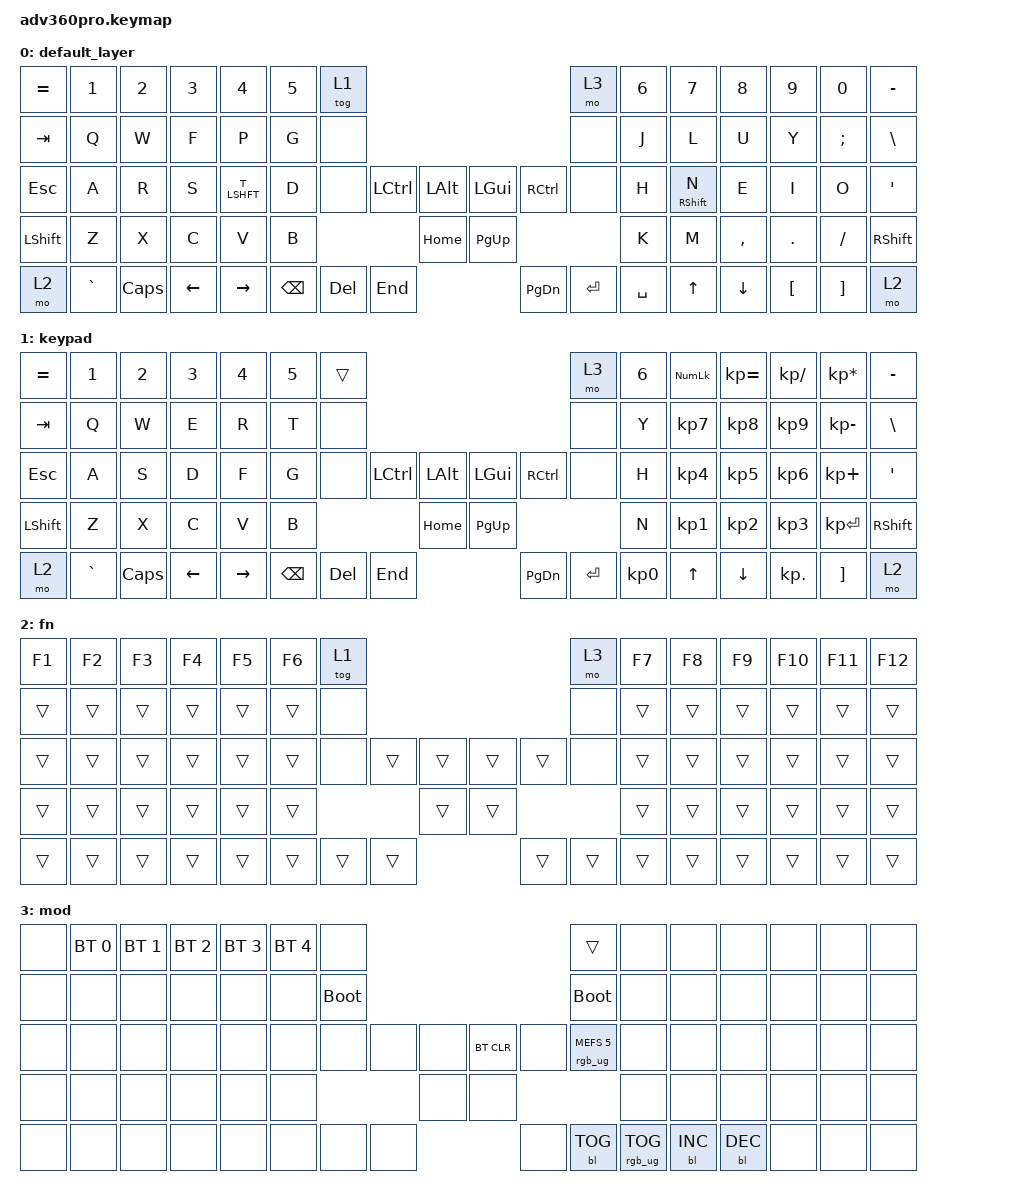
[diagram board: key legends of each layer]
#include "adv360pro_keypos.h"
#include "zmk_helper.h"

#define ___ &trans

/* Layer references  */
#define COLEMAK 0
#define QWERTY 1
#define NUM 2
#define SYM 3
#define FN 4
#define MOD 5
#define MS 6
#define NAV 7

/* Global settings */
#include "general.h"

/* Home row mods */
#include "homerow_mods.h"

/* Macros and shortcuts */
#include "custom_behaviors.h"
#include <behaviors.dtsi>
#include <dt-bindings/zmk/backlight.h>
#include <dt-bindings/zmk/bt.h>
#include <dt-bindings/zmk/keys.h>
#include <dt-bindings/zmk/rgb.h>

/ {
    behaviors {
    };

    macros {
    };

    keymap {
        compatible = "zmk,keymap";

        default_layer {
            bindings = <
&kp EQUAL  &kp N1     &kp N2    &kp N3    &kp N4       &kp N5  &tog 1                                                                    &mo 3  &kp N6  &kp N7       &kp N8     &kp N9    &kp N0         &kp MINUS
&kp TAB    &kp Q      &kp W     &kp F     &kp P        &kp G   &none                                                                     &none  &kp J   &kp L        &kp U      &kp Y     &kp SEMICOLON  &kp BSLH
&kp ESC    &kp A      &kp R     &kp S     T_LSHFT  &kp D   &none             &kp LCTRL  &kp LALT    &kp LGUI   &kp RCTRL             &none  &kp H   &hmr RSHFT N  &kp E      &kp I     &kp O          &kp SQT
&kp LSHFT  &kp Z      &kp X     &kp C     &kp V        &kp B                                &kp HOME    &kp PG_UP                               &kp K   &kp M        &kp COMMA  &kp DOT   &kp FSLH       &kp RSHFT
&mo 2      &kp GRAVE  &kp CAPS  &kp LEFT  &kp RIGHT                    &kp BSPC  &kp DEL    &kp END     &kp PG_DN  &kp ENTER  &kp SPACE                 &kp UP       &kp DOWN   &kp LBKT  &kp RBKT       &mo 2
            >;
        };

        keypad {
            bindings = <
&kp EQUAL  &kp N1     &kp N2    &kp N3    &kp N4     &kp N5  &trans                                                                    &mo 3  &kp N6  &kp KP_NUM  &kp KP_EQUAL  &kp KP_DIVIDE  &kp KP_MULTIPLY  &kp MINUS
&kp TAB    &kp Q      &kp W     &kp E     &kp R      &kp T   &none                                                                     &none  &kp Y   &kp KP_N7   &kp KP_N8     &kp KP_N9      &kp KP_MINUS     &kp BSLH
&kp ESC    &kp A      &kp S     &kp D     &kp F      &kp G   &none             &kp LCTRL  &kp LALT    &kp LGUI   &kp RCTRL             &none  &kp H   &kp KP_N4   &kp KP_N5     &kp KP_N6      &kp KP_PLUS      &kp SQT
&kp LSHFT  &kp Z      &kp X     &kp C     &kp V      &kp B                                &kp HOME    &kp PG_UP                               &kp N   &kp KP_N1   &kp KP_N2     &kp KP_N3      &kp KP_ENTER     &kp RSHFT
&mo 2      &kp GRAVE  &kp CAPS  &kp LEFT  &kp RIGHT                  &kp BSPC  &kp DEL    &kp END     &kp PG_DN  &kp ENTER  &kp KP_N0                 &kp UP      &kp DOWN      &kp KP_DOT     &kp RBKT         &mo 2
            >;
        };

        fn {
            bindings = <
&kp F1  &kp F2  &kp F3  &kp F4  &kp F5  &kp F6  &tog 1                                                    &mo 3  &kp F7  &kp F8  &kp F9  &kp F10  &kp F11  &kp F12
&trans  &trans  &trans  &trans  &trans  &trans  &none                                                     &none  &trans  &trans  &trans  &trans   &trans   &trans
&trans  &trans  &trans  &trans  &trans  &trans  &none           &trans  &trans    &trans  &trans          &none  &trans  &trans  &trans  &trans   &trans   &trans
&trans  &trans  &trans  &trans  &trans  &trans                          &trans    &trans                         &trans  &trans  &trans  &trans   &trans   &trans
&trans  &trans  &trans  &trans  &trans                  &trans  &trans  &trans    &trans  &trans  &trans                 &trans  &trans  &trans   &trans   &trans
            >;
        };

        mod {
            bindings = <
&none  &bt BT_SEL 0  &bt BT_SEL 1  &bt BT_SEL 2  &bt BT_SEL 3  &bt BT_SEL 4  &none                                                                        &trans                  &none  &none       &none       &none  &none  &none
&none  &none         &none         &none         &none         &none         &bootloader                                                                  &bootloader             &none  &none       &none       &none  &none  &none
&none  &none         &none         &none         &none         &none         &none               &none  &none    &bt BT_CLR  &none                        &rgb_ug RGB_MEFS_CMD 5  &none  &none       &none       &none  &none  &none
&none  &none         &none         &none         &none    &none                                    &none    &none                                                            &none  &none       &none       &none  &none  &none
&none  &none         &none         &none         &none                                    &none  &none  &none    &none       &bl BL_TOG  &rgb_ug RGB_TOG                                 &bl BL_INC  &bl BL_DEC  &none  &none  &none
            >;
        };
    };
};
